# M46B register map
File version: 2.0.2.1
Registers are 32-bit, read-write, reset 0x0 unless marked. A register's access mark holds for its fields unless they carry their own. Offsets are from the block's base; [hi:lo] are bit positions; {n}, {i} and the like mark numbered series.

## PJ — Port J
Base 0x400C0800
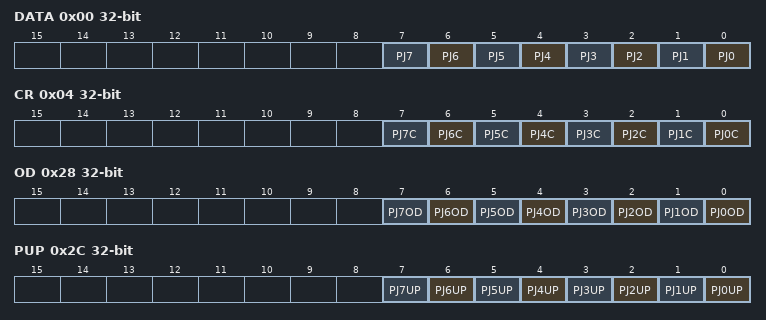
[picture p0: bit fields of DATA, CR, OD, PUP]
0x00 DATA — Port J Data Register
  [n] PJ{n} (n=0..7)
0x04 CR — Port J Output Control Register
  [n] PJ{n}C (n=0..7)
{0x4+4i} FR{i} (i=1..3) — Port J Function Register {i}
  [7] PJ7F{i}
0x28 OD — Port J Open Drain Control Register
  [n] PJ{n}OD (n=0..7)
0x2C PUP — Port J Pull-up Control Register
  [n] PJ{n}UP (n=0..7)
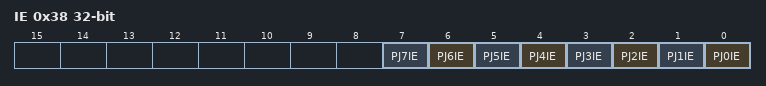
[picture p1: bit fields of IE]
0x38 IE — Port J Input Control Register
  [n] PJ{n}IE (n=0..7)

## PK — Port K
Base 0x400C0900
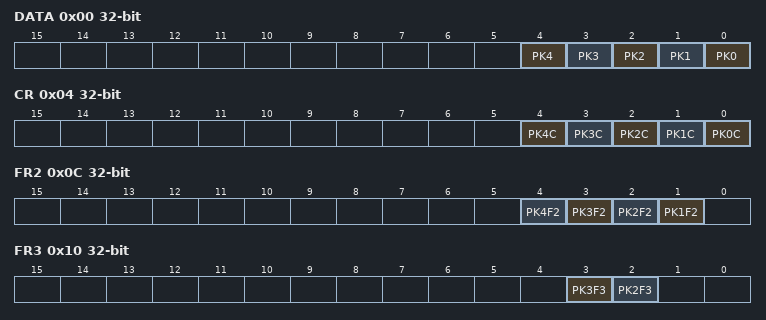
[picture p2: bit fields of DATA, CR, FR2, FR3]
0x00 DATA — Port K Data Register
  [n] PK{n} (n=0..4)
0x04 CR — Port K Output Control Register
  [n] PK{n}C (n=0..4)
0x0C FR2 — Port K Function Register 2
  [n] PK{n}F2 (n=1..4)
0x10 FR3 — Port K Function Register 3
  [3] PK3F3, [2] PK2F3
0x14 FR4 — Port K Function Register 4
  [1] PK1F4
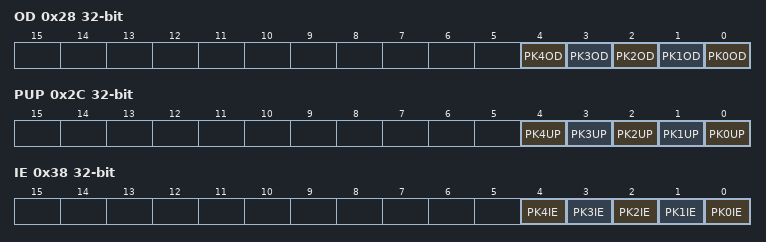
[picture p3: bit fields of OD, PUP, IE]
0x28 OD — Port K Open Drain Control Register
  [n] PK{n}OD (n=0..4)
0x2C PUP — Port K Pull-up Control Register
  [n] PK{n}UP (n=0..4)
0x38 IE — Port K Input Control Register
  [n] PK{n}IE (n=0..4)

## PL — Port L
Base 0x400C0A00
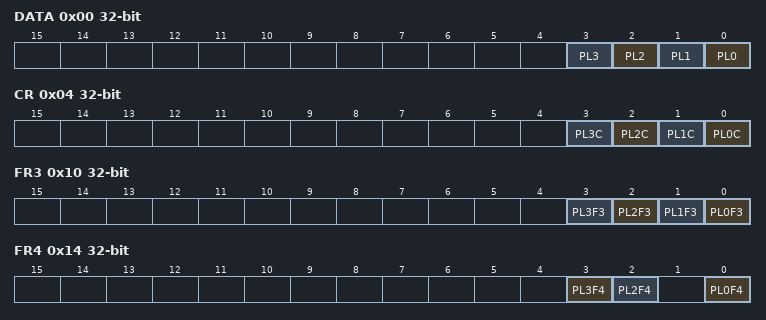
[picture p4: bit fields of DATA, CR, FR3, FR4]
0x00 DATA — Port L Data Register
  [n] PL{n} (n=0..3)
0x04 CR — Port L Output Control Register
  [n] PL{n}C (n=0..3)
0x10 FR3 — Port L Function Register 3
  [n] PL{n}F3 (n=0..3)
0x14 FR4 — Port L Function Register 4
  [3] PL3F4, [2] PL2F4, [0] PL0F4
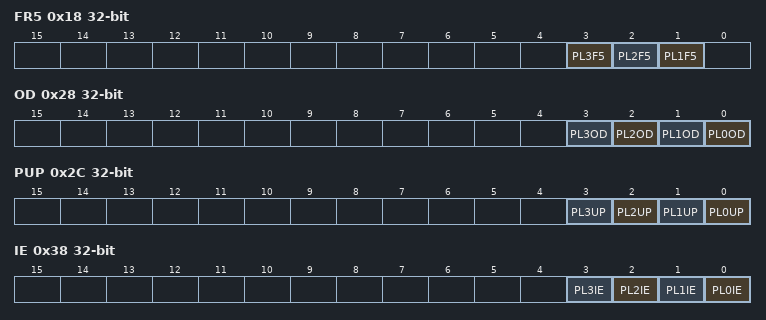
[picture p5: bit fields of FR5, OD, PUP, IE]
0x18 FR5 — Port L Function Register 5
  [3] PL3F5, [2] PL2F5, [1] PL1F5
0x1C FR6 — Port L Function Register 6
  [3] PL3F6
0x28 OD — Port L Open Drain Control Register
  [n] PL{n}OD (n=0..3)
0x2C PUP — Port L Pull-up Control Register
  [n] PL{n}UP (n=0..3)
0x38 IE — Port L Input Control Register
  [n] PL{n}IE (n=0..3)

## TB0 — 16-bit Timer_Event Counter (TB)
Base 0x400C4000
Same registers: TB1 0x400C4100, TB2 0x400C4200, TB3 0x400C4300, TB4 0x400C4400, TB5 0x400C4500, TB6 0x400C4600, TB7 0x400C4700
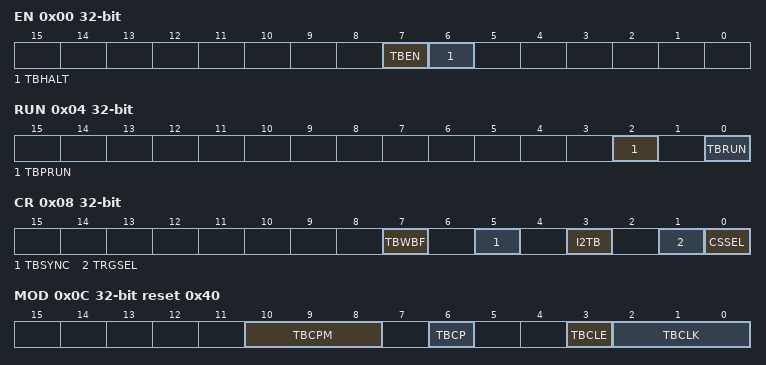
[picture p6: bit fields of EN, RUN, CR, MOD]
0x00 EN — TB Enable Register
  [7] TBEN, [6] TBHALT
0x04 RUN — TB RUN Register
  [2] TBPRUN, [0] TBRUN
0x08 CR — TB Control Register
  [7] TBWBF, [5] TBSYNC, [3] I2TB, [1] TRGSEL, [0] CSSEL
0x0C MOD reset 0x40 — TB Mode Register
  [10:8] TBCPM, [6] TBCP wo, [3] TBCLE, [2:0] TBCLK
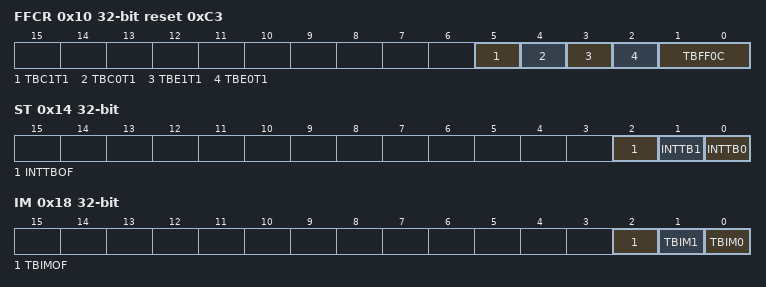
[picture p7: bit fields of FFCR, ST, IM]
0x10 FFCR reset 0xC3 — TB Flip-Flop Control Register
  [5] TBC1T1, [4] TBC0T1, [3] TBE1T1, [2] TBE0T1, [1:0] TBFF0C
0x14 ST ro — TB Status Register
  [2] INTTBOF, [1] INTTB1, [0] INTTB0
0x18 IM — TB Interrupt Mask Register
  [2] TBIMOF, [1] TBIM1, [0] TBIM0
0x1C UC ro — TB Up-counter Capture Register
  [15:0] TBUC
0x20 RG0 — TB RG0 Timer Register
  [15:0] TBRG0
0x24 RG1 — TB RG1 Timer Register
  [15:0] TBRG1
0x28 CP0 ro (reset mask 0xFFFF0000) — TB CP0 Capture Register
  [15:0] TBCP0
0x2C CP1 ro (reset mask 0xFFFF0000) — TB CP1 Capture Register
  [15:0] TBCP1

## MT0 — 16-bit Multi-Purpose Timer (MPT-TMR_IGBT)
Base 0x400C7000
Same registers: MT1 0x400C7100, MT2 0x400C7200, MT3 0x400C7300
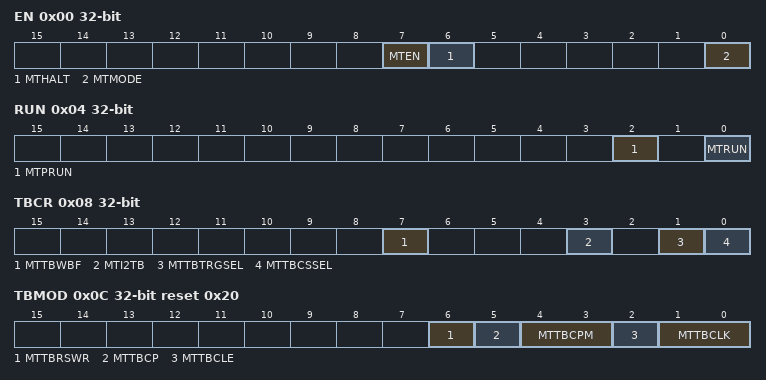
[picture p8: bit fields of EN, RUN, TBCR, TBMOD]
0x00 EN — MPT Enable Register
  [7] MTEN, [6] MTHALT, [0] MTMODE
0x04 RUN — MPT RUN Register
  [2] MTPRUN, [0] MTRUN
0x08 TBCR — MPT Control Register
  [7] MTTBWBF, [3] MTI2TB, [1] MTTBTRGSEL, [0] MTTBCSSEL
0x0C TBMOD reset 0x20 — MPT Mode Register
  [6] MTTBRSWR, [5] MTTBCP wo, [4:3] MTTBCPM, [2] MTTBCLE, [1:0] MTTBCLK
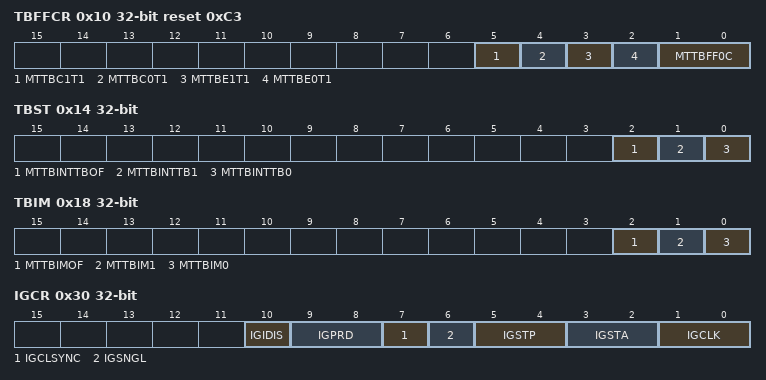
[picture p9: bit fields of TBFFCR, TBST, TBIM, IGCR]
0x10 TBFFCR reset 0xC3 — MPT Flip-Flop Control Register
  [5] MTTBC1T1, [4] MTTBC0T1, [3] MTTBE1T1, [2] MTTBE0T1, [1:0] MTTBFF0C
0x14 TBST ro — MPT Status Register
  [2] MTTBINTTBOF, [1] MTTBINTTB1, [0] MTTBINTTB0
0x18 TBIM — MPT Interrupt Mask Register
  [2] MTTBIMOF, [1] MTTBIM1, [0] MTTBIM0
0x1C TBUC ro — MPT Read Capture Register
  [15:0] MTUC
0x20 RG0 — MPT RG0 Timer Register
  [15:0] MTRG0
0x24 RG1 — MPT RG1 Timer Register
  [15:0] MTRG1
0x28 CP0 ro — MPT CP0 Capture Register
  [15:0] MTCP0
0x2C CP1 ro — MPT CP1 Capture Register
  [15:0] MTCP1
0x30 IGCR — IGBT Control Register
  [10] IGIDIS, [9:8] IGPRD, [7] IGCLSYNC, [6] IGSNGL, [5:4] IGSTP, [3:2] IGSTA, [1:0] IGCLK
0x34 IGRESTA wo — IGBT Timer Restart Register
  [0] IGRESTA
0x38 IGST ro — IGBT Timer Status Register
  [0] IGST
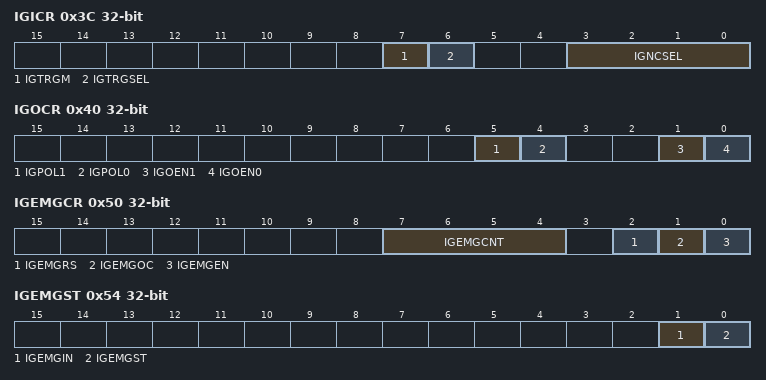
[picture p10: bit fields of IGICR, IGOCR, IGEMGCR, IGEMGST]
0x3C IGICR — IGBT Input Control Register
  [7] IGTRGM, [6] IGTRGSEL, [3:0] IGNCSEL
0x40 IGOCR — IGBT Output Control Register
  [5] IGPOL1, [4] IGPOL0, [1] IGOEN1, [0] IGOEN0
{0x3C+4i} IGRG{i} (i=2..4) — IGBT RG{i} Timer Register
  [15:0] IGRG{i}
0x50 IGEMGCR — IGBT EMG Control Register
  [7:4] IGEMGCNT, [2] IGEMGRS wo, [1] IGEMGOC, [0] IGEMGEN
0x54 IGEMGST ro — IGBT EMG Status Register
  [1] IGEMGIN, [0] IGEMGST
0x58 IGTRG — IGBT Trigger Status Register
  [15:0] IGTRG
